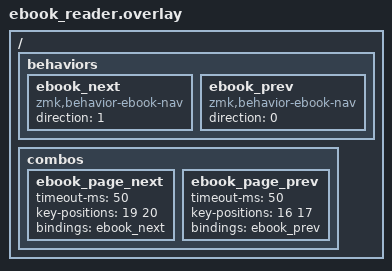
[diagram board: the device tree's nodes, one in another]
/*
 * Display hardware configured by hillside_view_left.overlay.
 *
 * TODO: behaviors and combos live here instead of hillside_view.keymap because
 * CONFIG_* Kconfig macros are not available to the DTS preprocessor for keymap
 * files in user config dirs (no -include autoconf.h passed). Ideal fix: either
 * investigate how to pass Kconfig flags to the keymap DTS preprocessor, or use
 * a dedicated hillside_view_ebook.keymap that includes hillside_view_common.dtsi
 * and adds ebook nodes directly without any #ifdef guard.
 */

/ {
    behaviors {
        ebook_next: ebook_next {
            compatible = "zmk,behavior-ebook-nav";
            #binding-cells = <0>;
            direction = <1>;
        };
        ebook_prev: ebook_prev {
            compatible = "zmk,behavior-ebook-nav";
            #binding-cells = <0>;
            direction = <0>;
        };
    };

    combos {
        ebook_page_next {
            timeout-ms = <50>;
            key-positions = <19 20>;  /* J + K = next page */
            bindings = <&ebook_next>;
        };

        ebook_page_prev {
            timeout-ms = <50>;
            key-positions = <16 17>;  /* F + G = prev page */
            bindings = <&ebook_prev>;
        };
    };
};
